# nrfshape_application register map
Vendor: Nordic-shaped; Series: nrfshape; File version: 1
A 32-bit Arm Cortex-M33 system-on-chip, in outline
CPU: CM33 r0p4, little endian, MPU, FPU, 3 interrupt priority bits, 270 interrupts, 4 SAU regions
Registers are 32-bit, access not given, reset 0x0 unless marked. A register's access mark holds for its fields unless they carry their own. Offsets are from the block's base; lines under a group give offsets from that group; [hi:lo] are bit positions; {n}, {i} and the like mark numbered series; 'fields as' and 'values as' point back to an identical list; <NAME> marks a mode.

## Memory map
0x12F00000 ICACHEDATA_S size 0x1000 — CACHEDATA
0x40042000 DPPIC00_NS — Distributed programmable peripheral interconnect controller 0
0x4004A000 UARTE00_NS — UART with EasyDMA 0
0x400D8200 P1_NS — GPIO Port 1
0x4010A000 P0_NS — GPIO Port 0
0x50040000 SPU00_S size 0x1000 — System protection unit 0
0x50042000 DPPIC00_S — Distributed programmable peripheral interconnect controller 1
0x50048000 GLOBAL_CRACEN_S — CRACEN
0x5004A000 UARTE00_S — UART with EasyDMA 1
0x500D8200 P1_S — GPIO Port 1, secure

## Interrupts
64 SPU00 (SPU00_S)
72 CRACEN (GLOBAL_CRACEN_S)
74 SERIAL00 (UARTE00_NS, UARTE00_S)

## ICACHEDATA_S — CACHEDATA
Base 0x12F00000
{0x0+0x40*i} SET[{i}] (i=0..3) group — Unspecified
  {0x0+0x20*j} WAY[{j}] (j=0..1) group — Unspecified
    {0x0+8k} DU[{k}] (k=0..3) group — Unspecified
      {0x0+4l} DATA[{l}] (l=0..1) rw — Description collection: Cache data bits for DATA[q] in DU[p] of SET[n], WAY[o].
        [31:0] Data ro

## SPU00_S — System protection unit 0
Base 0x50040000
0x100 EVENTS_PERIPHACCERR rw — A security violation has been detected on one or several peripherals
  [0] EVENTS_PERIPHACCERR
    0=NotGenerated (Event not generated); 1=Generated (Event generated)
{0x500+4i} PERIPH[{i}] (i=0..63) group — Unspecified
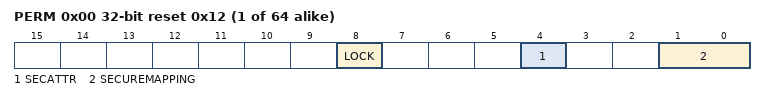
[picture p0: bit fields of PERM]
  0x00 PERM rw-once reset 0x12 — Description cluster: Get and set the applicable access permissions for the peripheral slave index n
    [8] LOCK write-1-sets
    [4] SECATTR
    [1:0] SECUREMAPPING ro
      0=NonSecure; 1=Secure; 2=UserSelectable; 3=Split
0x600 FEATURE group — Unspecified
  0x80 DPPIC group — Unspecified
    {0x0+4k} CH[{k}] (k=0..23) — Description collection: Security configuration for channel n of DPPIC.
    {0x60+4k} CHG[{k}] (k=0..7) — Description collection: Security configuration for channel group n of DPPIC.
  {0x100+0x80*j} GPIO[{j}] (j=0..1) group — Unspecified
    {0x0+4k} PIN[{k}] (k=0..31) — Description collection: Security configuration for GPIO pin.
  0x100 CRACEN group (alternate view of GPIO[*]) — Unspecified
    0x00 SEED — Configuration for CRACEN SEED
    0x04 CRACENCORE — Configuration for CRACEN core

## DPPIC00_NS — Distributed programmable peripheral interconnect controller 0
Base 0x40042000
Same registers: DPPIC00_S 0x50042000
{0x0+8i} TASKS_CHG[{i}] (i=0..5) group — Channel group tasks
  0x00 EN wo — Description cluster: Enable channel group n
  0x04 DIS wo — Description cluster: Disable channel group n
{0x80+8i} SUBSCRIBE_CHG[{i}] (i=0..5) group — Subscribe configuration for tasks
  0x00 EN
  0x04 DIS
0x500 CHEN — Channel enable register
{0x800+4i} CHG[{i}] (i=0..5) — Description collection: Channel group n

## GLOBAL_CRACEN_S — CRACEN
Base 0x50048000
0x400 ENABLE — Enable CRACEN peripheral modules.

## UARTE00_NS — UART with EasyDMA 0
Base 0x4004A000
Same registers: UARTE00_S 0x5004A000
0x00 TASKS_STARTRX wo
0x04 TASKS_STOPRX wo
0x80 SUBSCRIBE_STARTRX
0x100 EVENTS_CTS
0x14C EVENTS_DMA group — Peripheral events.
  0x00 RX group — Peripheral events.
    0x00 END
    0x04 READY
    0x08 BUSERROR
  0x1C TX group — Peripheral events.
    0x00 END
    0x04 READY
0x300 INTEN
0x480 ERRORSRC rw-once — Error source
0x500 ENABLE — Enable UART
  [3:0] ENABLE
    0=Disabled; 8=Enabled
0x524 BAUDRATE reset 0x4000000
0x56C CONFIG
0x604 PSEL group — Unspecified
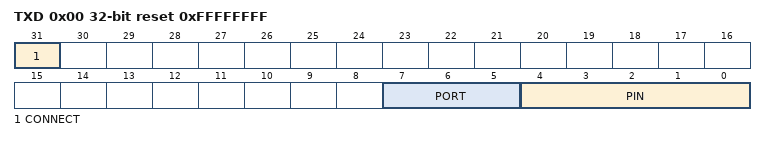
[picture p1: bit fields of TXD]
  0x00 TXD reset 0xFFFFFFFF
    [31] CONNECT
      0=Connected; 1=Disconnected
    [7:5] PORT
    [4:0] PIN
  0x04 CTS reset 0xFFFFFFFF
  0x08 RXD reset 0xFFFFFFFF
  0x0C RTS reset 0xFFFFFFFF
0x700 DMA group — Unspecified
  0x00 RX group — Unspecified
    0x04 PTR
    0x08 MAXCNT
    0x0C AMOUNT ro
  0x38 TX group — Unspecified
    0x04 PTR
    0x08 MAXCNT
    0x0C AMOUNT ro

## P0_NS — GPIO Port 0
Base 0x4010A000
Same registers: P1_NS 0x400D8200, P1_S 0x500D8200
0x00 OUT
0x04 OUTSET
0x10 IN ro
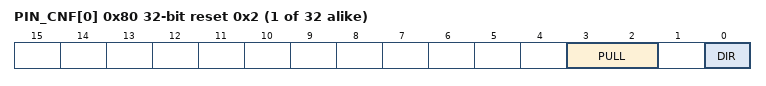
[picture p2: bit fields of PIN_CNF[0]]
{0x80+4i} PIN_CNF[{i}] (i=0..31) reset 0x2 — Description collection: Pin n configuration of GPIO pin
  [3:2] PULL
    0=Disabled; 1=Pulldown; 3=Pullup
  [0] DIR
    0=Input; 1=Output
